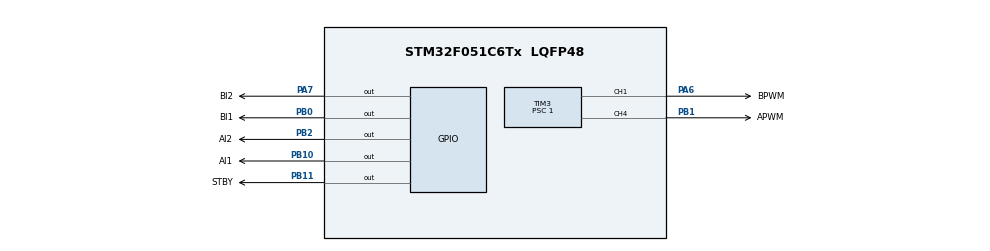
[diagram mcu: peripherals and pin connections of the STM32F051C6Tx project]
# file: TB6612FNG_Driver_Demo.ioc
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Mcu.Family=STM32F0
TIM3.AutoReloadPreload=TIM_AUTORELOAD_PRELOAD_ENABLE
PB11.GPIO_Label=STBY
PA6.GPIO_Label=BPWM
PB0.GPIO_Label=BI1
PB11.Signal=GPIO_Output
TIM3.Channel-PWM\ Generation4\ CH4=TIM_CHANNEL_4
ProjectManager.StackSize=0x400
ProjectManager.TargetToolchain=STM32CubeIDE
PB10.GPIO_Label=AI1
TIM3.Period=65535
TIM3.Channel-PWM\ Generation1\ CH1=TIM_CHANNEL_1
PB10.Signal=GPIO_Output
TIM3.ClockDivision=TIM_CLOCKDIVISION_DIV1
PB2.Signal=GPIO_Output
board=custom
TIM3.Prescaler=1
PB1.GPIO_Label=APWM
SH.S_TIM3_CH1.0=TIM3_CH1,PWM Generation1 CH1
Mcu.Name=STM32F051C6Tx
Mcu.Package=LQFP48
PA6.Signal=S_TIM3_CH1
PB1.Signal=S_TIM3_CH4
PA7.GPIO_Label=BI2
PB2.GPIO_Label=AI2
ProjectManager.HeapSize=0x200
PB0.Signal=GPIO_Output
VP_TIM3_VS_ClockSourceINT.Mode=Internal
SH.S_TIM3_CH4.0=TIM3_CH4,PWM Generation4 CH4
PA7.Signal=GPIO_Output

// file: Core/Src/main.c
/* USER CODE BEGIN Header */
/**
  ******************************************************************************
  * @file           : main.c
  * @brief          : Main program body
  ******************************************************************************
  * @attention
  *
  * <h2><center>&copy; Copyright (c) 2020 STMicroelectronics.
  * All rights reserved.</center></h2>
  *
  * This software component is licensed by ST under BSD 3-Clause license,
  * the "License"; You may not use this file except in compliance with the
  * License. You may obtain a copy of the License at:
  *                        opensource.org/licenses/BSD-3-Clause
  *
  ******************************************************************************
  */
/* USER CODE END Header */

#include "main.h"

/* USER CODE BEGIN Includes */
#include "TB6612FNG.h"
/* USER CODE END Includes */

TIM_HandleTypeDef htim3;

void SystemClock_Config(void);
static void MX_GPIO_Init(void);
static void MX_TIM3_Init(void);

int main(void)
{

  /* MCU Configuration--------------------------------------------------------*/

  /* Reset of all peripherals, Initializes the Flash interface and the Systick. */
  HAL_Init();

  /* Configure the system clock */
  SystemClock_Config();

  /* Initialize all configured peripherals */
  MX_GPIO_Init();
  MX_TIM3_Init();
  /* USER CODE BEGIN 2 */
  // NOTE: Definitions made on user labels from Code Generator

  // Constructing motorA pin structure.
  TB6612FNG_Motor motorA = {
		  .MOTOR = TB6612FNG_Motor_A,
		  .I1 = &(TB6612FNG_Pin){ .Port = AI1_GPIO_Port, .Pin = AI1_Pin },
		  .I2 = &(TB6612FNG_Pin){ .Port = AI2_GPIO_Port, .Pin = AI2_Pin },
		  .TIMER = &(TB6612FNG_Timer){ .htim = &htim3, .channel = TIM_CHANNEL_4}
  };
  // Assigning motorB to motorA (single motor mode)
  TB6612FNG_Motor motorB = motorA;

  // Constructing standby pin structure.
  TB6612FNG_Pin stby = { .Port = STBY_GPIO_Port, .Pin = STBY_Pin };

  // Initializing
  setupTB6612FNG(&htim3, &motorA, &motorB, &stby);
  /* USER CODE END 2 */

  /* Infinite loop */
  while (1)
  {

  }
}

void SystemClock_Config(void)
{
  RCC_OscInitTypeDef RCC_OscInitStruct = {0};
  RCC_ClkInitTypeDef RCC_ClkInitStruct = {0};

  /** Initializes the CPU, AHB and APB busses clocks
  */
  RCC_OscInitStruct.OscillatorType = RCC_OSCILLATORTYPE_HSI;
  RCC_OscInitStruct.HSIState = RCC_HSI_ON;
  RCC_OscInitStruct.HSICalibrationValue = RCC_HSICALIBRATION_DEFAULT;
  RCC_OscInitStruct.PLL.PLLState = RCC_PLL_NONE;
  if (HAL_RCC_OscConfig(&RCC_OscInitStruct) != HAL_OK)
  {
    Error_Handler();
  }
  /** Initializes the CPU, AHB and APB busses clocks
  */
  RCC_ClkInitStruct.ClockType = RCC_CLOCKTYPE_HCLK|RCC_CLOCKTYPE_SYSCLK
                              |RCC_CLOCKTYPE_PCLK1;
  RCC_ClkInitStruct.SYSCLKSource = RCC_SYSCLKSOURCE_HSI;
  RCC_ClkInitStruct.AHBCLKDivider = RCC_SYSCLK_DIV1;
  RCC_ClkInitStruct.APB1CLKDivider = RCC_HCLK_DIV1;

  if (HAL_RCC_ClockConfig(&RCC_ClkInitStruct, FLASH_LATENCY_0) != HAL_OK)
  {
    Error_Handler();
  }
}

static void MX_TIM3_Init(void)
{

  TIM_ClockConfigTypeDef sClockSourceConfig = {0};
  TIM_MasterConfigTypeDef sMasterConfig = {0};
  TIM_OC_InitTypeDef sConfigOC = {0};

  htim3.Instance = TIM3;
  htim3.Init.Prescaler = 1;
  htim3.Init.CounterMode = TIM_COUNTERMODE_UP;
  htim3.Init.Period = 65535;
  htim3.Init.ClockDivision = TIM_CLOCKDIVISION_DIV1;
  htim3.Init.AutoReloadPreload = TIM_AUTORELOAD_PRELOAD_ENABLE;
  if (HAL_TIM_Base_Init(&htim3) != HAL_OK)
  {
    Error_Handler();
  }
  sClockSourceConfig.ClockSource = TIM_CLOCKSOURCE_INTERNAL;
  if (HAL_TIM_ConfigClockSource(&htim3, &sClockSourceConfig) != HAL_OK)
  {
    Error_Handler();
  }
  if (HAL_TIM_PWM_Init(&htim3) != HAL_OK)
  {
    Error_Handler();
  }
  sMasterConfig.MasterOutputTrigger = TIM_TRGO_RESET;
  sMasterConfig.MasterSlaveMode = TIM_MASTERSLAVEMODE_DISABLE;
  if (HAL_TIMEx_MasterConfigSynchronization(&htim3, &sMasterConfig) != HAL_OK)
  {
    Error_Handler();
  }
  sConfigOC.OCMode = TIM_OCMODE_PWM1;
  sConfigOC.Pulse = 0;
  sConfigOC.OCPolarity = TIM_OCPOLARITY_HIGH;
  sConfigOC.OCFastMode = TIM_OCFAST_DISABLE;
  if (HAL_TIM_PWM_ConfigChannel(&htim3, &sConfigOC, TIM_CHANNEL_1) != HAL_OK)
  {
    Error_Handler();
  }
  if (HAL_TIM_PWM_ConfigChannel(&htim3, &sConfigOC, TIM_CHANNEL_4) != HAL_OK)
  {
    Error_Handler();
  }
  HAL_TIM_MspPostInit(&htim3);

}

static void MX_GPIO_Init(void)
{
  GPIO_InitTypeDef GPIO_InitStruct = {0};

  /* GPIO Ports Clock Enable */
  __HAL_RCC_GPIOA_CLK_ENABLE();
  __HAL_RCC_GPIOB_CLK_ENABLE();

  /*Configure GPIO pin Output Level */
  HAL_GPIO_WritePin(BI2_GPIO_Port, BI2_Pin, GPIO_PIN_RESET);

  /*Configure GPIO pin Output Level */
  HAL_GPIO_WritePin(GPIOB, BI1_Pin|AI2_Pin|AI1_Pin|STBY_Pin, GPIO_PIN_RESET);

  /*Configure GPIO pin : BI2_Pin */
  GPIO_InitStruct.Pin = BI2_Pin;
  GPIO_InitStruct.Mode = GPIO_MODE_OUTPUT_PP;
  GPIO_InitStruct.Pull = GPIO_NOPULL;
  GPIO_InitStruct.Speed = GPIO_SPEED_FREQ_LOW;
  HAL_GPIO_Init(BI2_GPIO_Port, &GPIO_InitStruct);

  /*Configure GPIO pins : BI1_Pin AI2_Pin AI1_Pin STBY_Pin */
  GPIO_InitStruct.Pin = BI1_Pin|AI2_Pin|AI1_Pin|STBY_Pin;
  GPIO_InitStruct.Mode = GPIO_MODE_OUTPUT_PP;
  GPIO_InitStruct.Pull = GPIO_NOPULL;
  GPIO_InitStruct.Speed = GPIO_SPEED_FREQ_LOW;
  HAL_GPIO_Init(GPIOB, &GPIO_InitStruct);

}

void Error_Handler(void)
{
}

/************************ (C) COPYRIGHT STMicroelectronics *****END OF FILE****/
